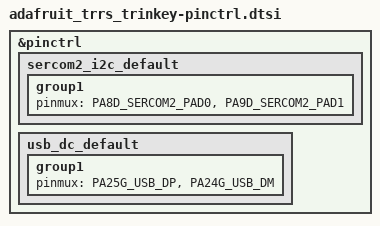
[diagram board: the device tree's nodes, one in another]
/*
 * Copyright (c) 2022 Gerson Fernando Budke <nandojve@gmail.com>
 * Copyright (c) 2025 Perry Naseck, MIT Media Lab <pnaseck@media.mit.edu>
 * SPDX-License-Identifier: Apache-2.0
 */

#include <dt-bindings/pinctrl/samd21-da1eXabcd-pinctrl.h>

&pinctrl {
	sercom2_i2c_default: sercom2_i2c_default {
		group1 {
			pinmux = <PA8D_SERCOM2_PAD0>,
				 <PA9D_SERCOM2_PAD1>;
		};
	};

	usb_dc_default: usb_dc_default {
		group1 {
			pinmux = <PA25G_USB_DP>,
				 <PA24G_USB_DM>;
		};
	};
};
